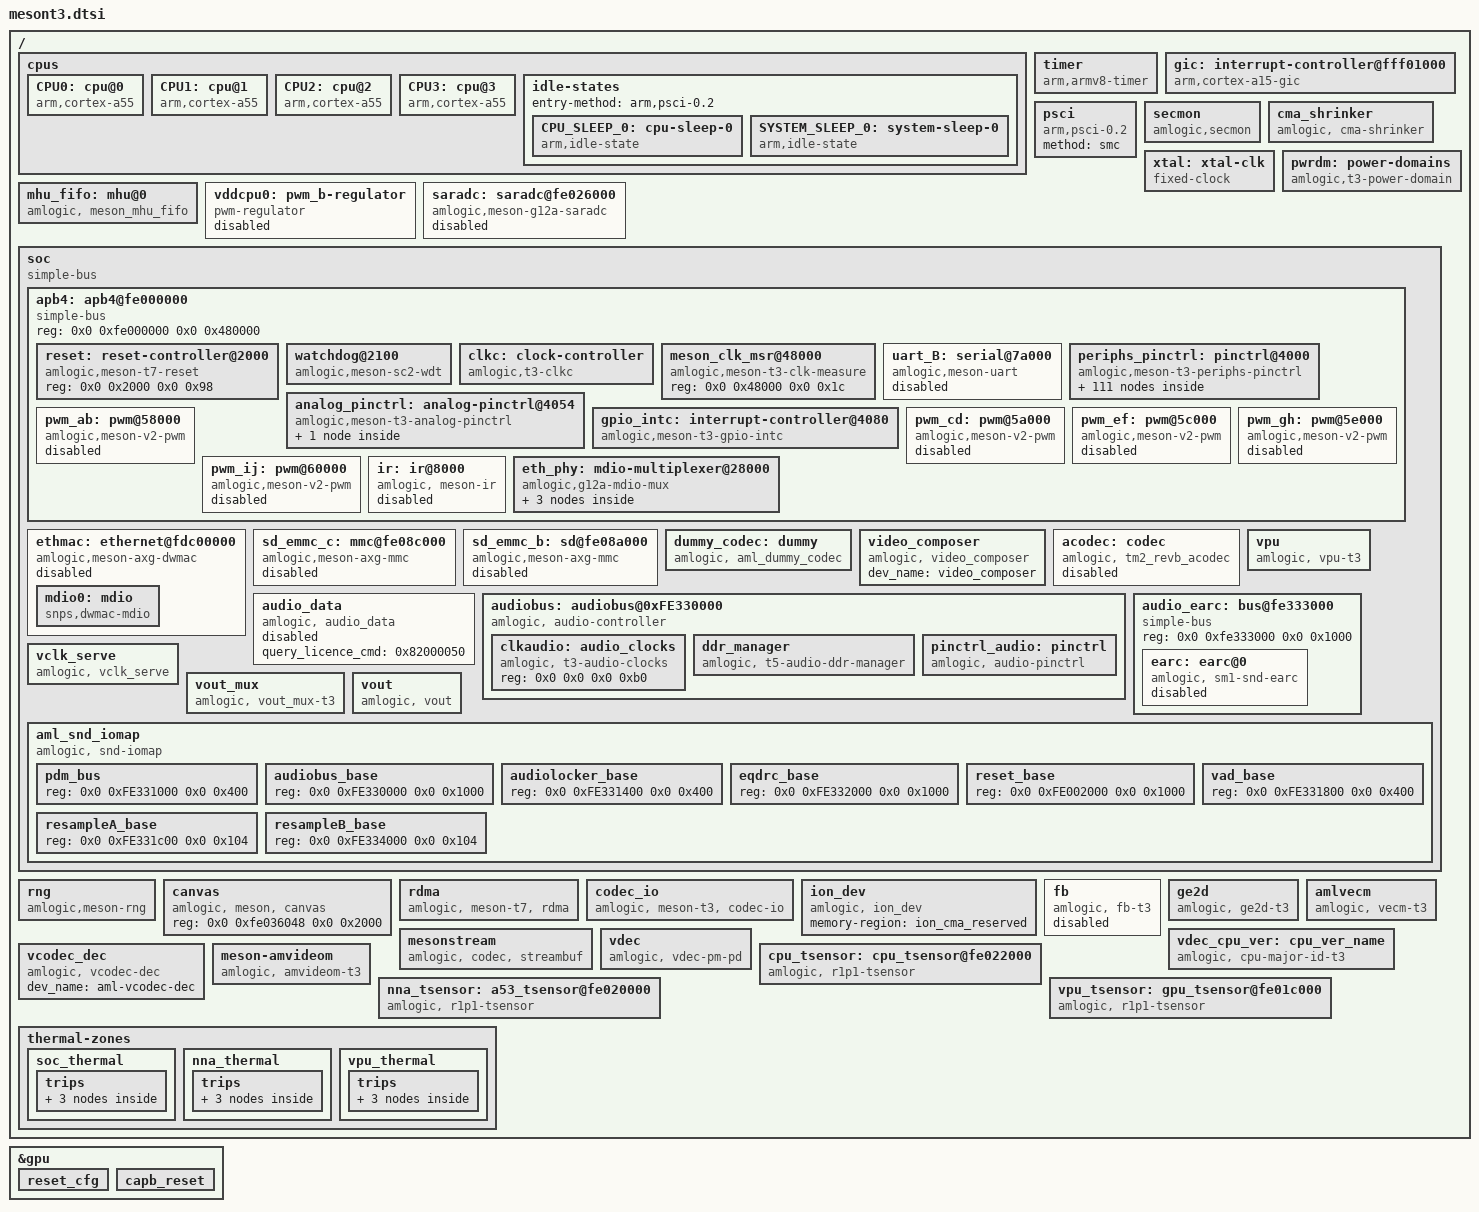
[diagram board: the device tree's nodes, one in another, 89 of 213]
// SPDX-License-Identifier: (GPL-2.0+ OR MIT)
/*
 * Copyright (c) 2021 Amlogic, Inc. All rights reserved.
 */

#include <dt-bindings/interrupt-controller/irq.h>
#include <dt-bindings/interrupt-controller/arm-gic.h>
#include <dt-bindings/reset/amlogic,meson-t3-reset.h>
#include <dt-bindings/clock/t3-clkc.h>
#include <dt-bindings/clock/amlogic,t3-audio-clk.h>
#include <dt-bindings/gpio/gpio.h>
#include <dt-bindings/gpio/meson-t3-gpio.h>
#include <dt-bindings/power/t3-pd.h>
#include <dt-bindings/pwm/pwm.h>
#include <dt-bindings/pwm/meson.h>
#include <dt-bindings/input/input.h>
#include <dt-bindings/input/meson_ir.h>
#include "meson-ir-map.dtsi"
#include "mesong12a-bifrost.dtsi"
/ {
	cpus:cpus {
		#address-cells = <2>;
		#size-cells = <0>;

		CPU0:cpu@0 {
			device_type = "cpu";
			compatible = "arm,cortex-a55","arm,armv8";
			reg = <0x0 0x0>;
			enable-method = "psci";
			cpu-idle-states = <&CPU_SLEEP_0 &SYSTEM_SLEEP_0>;
//			#cooling-cells = <2>;
//			clocks = <&clkc CLKID_CPU_CLK>,
//				<&clkc CLKID_CPU_DYN_CLK>,
//				<&clkc CLKID_SYS1_PLL>;
//			clock-names = "core_clk",
//				"low_freq_clk_parent",
//				"high_freq_clk_parent";
//			operating-points-v2 = <&cpu_opp_table1>;
			voltage-tolerance = <0>;
			clock-latency = <50000>;
			dynamic-power-coefficient = <230>;
		};

		CPU1:cpu@1{
			device_type = "cpu";
			compatible = "arm,cortex-a55","arm,armv8";
			reg = <0x0 0x1>;
			enable-method = "psci";
			cpu-idle-states = <&CPU_SLEEP_0 &SYSTEM_SLEEP_0>;
//			#cooling-cells = <2>;
//			clocks = <&clkc CLKID_CPU_CLK>,
//				<&clkc CLKID_CPU_DYN_CLK>,
//				<&clkc CLKID_SYS1_PLL>;
//			clock-names = "core_clk",
//				"low_freq_clk_parent",
//				"high_freq_clk_parent";
//			operating-points-v2 = <&cpu_opp_table1>;
			voltage-tolerance = <0>;
			clock-latency = <50000>;
			dynamic-power-coefficient = <230>;
		};

		CPU2:cpu@2 {
			device_type = "cpu";
			compatible = "arm,cortex-a55","arm,armv8";
			reg = <0x0 0x2>;
			enable-method = "psci";
			cpu-idle-states = <&CPU_SLEEP_0 &SYSTEM_SLEEP_0>;
//			#cooling-cells = <2>;
//			clocks = <&clkc CLKID_CPU_CLK>,
//				<&clkc CLKID_CPU_DYN_CLK>,
//				<&clkc CLKID_SYS1_PLL>;
//			clock-names = "core_clk",
//				"low_freq_clk_parent",
//				"high_freq_clk_parent";
//			operating-points-v2 = <&cpu_opp_table1>;
			voltage-tolerance = <0>;
			clock-latency = <50000>;
			dynamic-power-coefficient = <230>;
		};

		CPU3:cpu@3 {
			device_type = "cpu";
			compatible = "arm,cortex-a55","arm,armv8";
			reg = <0x0 0x3>;
			enable-method = "psci";
			cpu-idle-states = <&CPU_SLEEP_0 &SYSTEM_SLEEP_0>;
//			#cooling-cells = <2>;
//			clocks = <&clkc CLKID_CPU_CLK>,
//				<&clkc CLKID_CPU_DYN_CLK>,
//				<&clkc CLKID_SYS1_PLL>;
//			clock-names = "core_clk",
//				"low_freq_clk_parent",
//				"high_freq_clk_parent";
//			operating-points-v2 = <&cpu_opp_table1>;
			voltage-tolerance = <0>;
			clock-latency = <50000>;
		};

		idle-states {
			entry-method = "arm,psci-0.2";
			CPU_SLEEP_0: cpu-sleep-0 {
					compatible = "arm,idle-state";
					arm,psci-suspend-param = <0x0010000>;
					local-timer-stop;
					entry-latency-us = <4000>;
					exit-latency-us = <5000>;
					min-residency-us = <10000>;
			};
			SYSTEM_SLEEP_0: system-sleep-0 {
					compatible = "arm,idle-state";
					arm,psci-suspend-param = <0x0000000>;
					entry-latency-us = <0x3fffffff>;
					exit-latency-us = <0x40000000>;
					min-residency-us = <0xffffffff>;
			};
		};
	};

	timer {
		compatible = "arm,armv8-timer";
		interrupts = <GIC_PPI 13 0xff08>,
				<GIC_PPI 14 0xff08>,
				<GIC_PPI 11 0xff08>,
				<GIC_PPI 10 0xff08>;
	};

	gic: interrupt-controller@fff01000 {
		compatible = "arm,cortex-a15-gic", "arm,cortex-a9-gic";
		#interrupt-cells = <3>;
		#address-cells = <0>;
		interrupt-controller;
		reg = <0x0 0xfff01000 0 0x1000>,
		      <0x0 0xfff02000 0 0x0100>;
		interrupts = <GIC_PPI 9 0xf04>;
	};

	psci {
		compatible = "arm,psci-0.2";
		method = "smc";
	};

	secmon {
	    compatible = "amlogic,secmon";
		memory-region = <&secmon_reserved>;
		reserve_mem_size = <0x00300000>;
		in_base_func = <0x82000020>;
		out_base_func = <0x82000021>;
		clear_range = <0x05100000 0x200000>;
	};

	cma_shrinker: cma_shrinker {
		compatible = "amlogic, cma-shrinker";
		status = "okay";
		adj  = <0 100 200 250 900 950>;
		free = <8192 12288 16384 24576 28672 32768>;
	};

	xtal: xtal-clk {
		compatible = "fixed-clock";
		clock-frequency = <24000000>;
		clock-output-names = "xtal";
		#clock-cells = <0>;
	};

	pwrdm: power-domains {
		compatible = "amlogic,t3-power-domain";
		#power-domain-cells = <1>;
		status = "okay";
	};

	mhu_fifo: mhu@0 {
		status = "okay";
		compatible = "amlogic, meson_mhu_fifo";
		reg = <0x0 0xfe006000 0x0 0x1000>,  /* mhu wr fifo */
		      <0x0 0xfe007180 0x0 0x80>,   /* mhu set reg */
		      <0x0 0xfe007200 0x0 0x80>,   /* mhu clr reg */
		      <0x0 0xfe007280 0x0 0x80>,   /* mhu sts reg */
		      <0x0 0xfe007040 0x0 0xc0>;   /* mhu irqctrl reg */
		interrupts = <0 248 1>;   /* irq top */
		mbox-irqmax = <64>;
		mbox-irqctlr = <0>;
		mbox-nums = <4>;
		mbox-names = "dsp_dev",
			     "ap_to_dspa",
			     "ao_dev",
			     "ap_to_ao";
		mboxes = <&mhu_fifo 0>,
			 <&mhu_fifo 1>,
			 <&mhu_fifo 2>,
			 <&mhu_fifo 3>;
		mbox-id = <0x0 0x1 0x2 0x3>;
		mbox-wr-rd = <1>;
		#mbox-cells = <1>;
	};

	vddcpu0: pwm_b-regulator {
		compatible = "pwm-regulator";
		pwms = <&pwm_ab MESON_PWM_1 1500 0>;
		regulator-name = "vddcpu0";
		regulator-min-microvolt = <689000>;
		regulator-max-microvolt = <1049000>;
		regulator-always-on;
		max-duty-cycle = <1500>;
		/* Voltage Duty-Cycle */
		voltage-table = <1049000 0>,
				<1039000 3>,
				<1029000 6>,
				<1019000 9>,
				<1009000 12>,
				<999000 14>,
				<989000 17>,
				<979000 20>,
				<969000 23>,
				<959000 26>,
				<949000 29>,
				<939000 31>,
				<929000 34>,
				<919000 37>,
				<909000 40>,
				<899000 43>,
				<889000 45>,
				<879000 48>,
				<869000 51>,
				<859000 54>,
				<849000 56>,
				<839000 59>,
				<829000 62>,
				<819000 65>,
				<809000 68>,
				<799000 70>,
				<789000 73>,
				<779000 76>,
				<769000 79>,
				<759000 81>,
				<749000 84>,
				<739000 87>,
				<729000 89>,
				<719000 92>,
				<709000 95>,
				<699000 98>,
				<689000 100>;
		status = "disabled";
	};

	saradc: saradc@fe026000 {
		compatible = "amlogic,meson-g12a-saradc",
			   "amlogic,meson-saradc";
		status = "disabled";
		#io-channel-cells = <1>;
		clocks = <&xtal>,
		    <&clkc CLKID_SYS_CLK_SAR_ADC>,
		    <&clkc CLKID_SARADC>,
		    <&clkc CLKID_SARADC_SEL>;
		clock-names = "clkin", "core",
		    "adc_clk", "adc_sel";
		interrupts = <GIC_SPI 181 IRQ_TYPE_EDGE_RISING>;
		reg = <0x00 0xfe026000 0x00 0x48>;
	};

	soc {
		compatible = "simple-bus";
		#address-cells = <2>;
		#size-cells = <2>;
		ranges;

		apb4: apb4@fe000000 {
			compatible = "simple-bus";
			reg = <0x0 0xfe000000 0x0 0x480000>;
			#address-cells = <2>;
			#size-cells = <2>;
			ranges = <0x0 0x0 0x0 0xfe000000 0x0 0x480000>;

			reset: reset-controller@2000 {
				compatible = "amlogic,meson-t7-reset";
				reg = <0x0 0x2000 0x0 0x98>;
				#reset-cells = <1>;
			};

			watchdog@2100 {
				compatible = "amlogic,meson-sc2-wdt";
				status = "okay";
				/* 0:userspace, 1:kernel */
				amlogic,feed_watchdog_mode = <1>;
				reg = <0x0 0x2100 0x0 0x10>;
				clocks = <&xtal>;
			};

			clkc: clock-controller {
				compatible = "amlogic,t3-clkc";
				#clock-cells = <1>;
				reg = <0x0 0x0 0x0 0x230>,
				      <0x0 0x8000 0x0 0x3e4>,
				      <0x0 0xe140 0x0 0x20>;
				reg-names = "basic", "pll",
					    "cpu_clk";
				clocks = <&xtal>;
				clock-names = "xtal";
				status = "okay";
			};

			meson_clk_msr@48000 {
				compatible = "amlogic,meson-t3-clk-measure";
				reg = <0x0 0x48000 0x0 0x1c>;
			};

			uart_B: serial@7a000 {
				compatible = "amlogic,meson-uart";
				reg = <0x0 0x7a000 0x0 0x18>;
				interrupts = <0 169 1>;
				status = "disabled";
				clocks = <&xtal>;
				clock-names = "clk_uart";
				xtal_tick_en = <2>;
				fifosize = < 64 >;
				pinctrl-names = "default";
				//pinctrl-0 = <&a_uart_pins1>;
			};

			periphs_pinctrl: pinctrl@4000 {
				compatible = "amlogic,meson-t3-periphs-pinctrl";
				#address-cells = <2>;
				#size-cells = <2>;
				ranges;

				gpio: bank@4000 {
					reg = <0x0 0x4000 0x0 0x0054>,
					      <0x0 0x40c0 0x0 0x030c>;
					reg-names = "mux", "gpio";
					gpio-controller;
					#gpio-cells = <2>;
					gpio-ranges = <&periphs_pinctrl 0 0 136>;
				};
			};

			analog_pinctrl: analog-pinctrl@4054 {
				compatible = "amlogic,meson-t3-analog-pinctrl";
				#address-cells = <2>;
				#size-cells = <2>;
				ranges;

				analog_gpio: analog-bank@4054 {
					reg = <0x0 0x4054 0x0 0x0008>,
					      <0x0 0x43cc 0x0 0x0008>;
					reg-names = "mux", "gpio";
					gpio-controller;
					#gpio-cells = <2>;
					gpio-ranges = <&analog_pinctrl 0 0 3>;
				};
			};

			gpio_intc: interrupt-controller@4080 {
				compatible = "amlogic,meson-t3-gpio-intc",
					     "amlogic,meson-gpio-intc";
				reg = <0x0 0x4080 0x0 0x20>;
				interrupt-controller;
				#interrupt-cells = <2>;
				amlogic,channel-interrupts =
					<10 11 12 13 14 15 16 17 18 19 20 21>;
			};

			pwm_ab: pwm@58000 {
				compatible = "amlogic,meson-v2-pwm";
				reg = <0x0 0x58000 0x0 0x24>;
				#pwm-cells = <3>;
				clocks = <&clkc CLKID_PWM_A>,
						<&clkc CLKID_PWM_B>;
				clock-names = "clkin0", "clkin1";
				status = "disabled";
			};

			pwm_cd: pwm@5a000 {
				compatible = "amlogic,meson-v2-pwm";
				reg = <0x0 0x5a000 0x0 0x24>;
				#pwm-cells = <3>;
				clocks = <&clkc CLKID_PWM_C>,
						<&clkc CLKID_PWM_D>;
				clock-names = "clkin0", "clkin1";
				status = "disabled";
			};

			pwm_ef: pwm@5c000 {
				compatible = "amlogic,meson-v2-pwm";
				reg = <0x0 0x5c000 0x0 0x24>;
				#pwm-cells = <3>;
				clocks = <&clkc CLKID_PWM_E>,
						<&clkc CLKID_PWM_F>;
				clock-names = "clkin0", "clkin1";
				status = "disabled";
			};

			pwm_gh: pwm@5e000 {
				compatible = "amlogic,meson-v2-pwm";
				reg = <0x0 0x5e000 0x0 0x24>;
				#pwm-cells = <3>;
				clocks = <&clkc CLKID_PWM_G>,
						<&clkc CLKID_PWM_H>;
				clock-names = "clkin0", "clkin1";
				status = "disabled";
			};

			pwm_ij: pwm@60000 {
				compatible = "amlogic,meson-v2-pwm";
				reg = <0x0 0x60000 0x0 0x24>;
				#pwm-cells = <3>;
				clocks = <&clkc CLKID_PWM_I>,
						<&clkc CLKID_PWM_J>;
				clock-names = "clkin0", "clkin1";
				status = "disabled";
			};

			ir: ir@8000 {
				compatible = "amlogic, meson-ir";
				reg = <0x0 0x84040 0x0 0x44>,
					<0x0 0x84000 0x0 0x20>;
				status = "disabled";
				protocol = <REMOTE_TYPE_NEC>;
				interrupts = <GIC_SPI 22 IRQ_TYPE_EDGE_RISING>;
				map = <&custom_maps>;
				max_frame_time = <200>;
			};

			eth_phy: mdio-multiplexer@28000 {
				compatible = "amlogic,g12a-mdio-mux";
				reg = <0x0 0x28000 0x0 0xa4>;

				clocks = <&clkc CLKID_SYS_CLK_ETHPHY>,
					 <&xtal>,
					 <&clkc CLKID_MPLL_50M>;
				clock-names = "pclk", "clkin0", "clkin1";
				mdio-parent-bus = <&mdio0>;
				#address-cells = <1>;
				#size-cells = <0>;
				enet_type = <5>;
				tx_amp_src = <0xFE010330>;

				ext_mdio: mdio@0 {
					reg = <0>;
					#address-cells = <1>;
					#size-cells = <0>;
				};

				int_mdio: mdio@1 {
					reg = <1>;
					#address-cells = <1>;
					#size-cells = <0>;

					internal_ephy: ethernet_phy@8 {
						compatible = "ethernet-phy-id0180.3301",
							     "ethernet-phy-ieee802.3-c22";
						interrupts = <GIC_SPI 340 IRQ_TYPE_LEVEL_HIGH>;
						reg = <8>;
						max-speed = <100>;
					};
				};
			};
		};

		ethmac: ethernet@fdc00000 {
			compatible = "amlogic,meson-axg-dwmac",
				     "snps,dwmac-3.70a",
				     "snps,dwmac";
			reg = <0x0 0xfdc00000 0x0 0x10000>,
			      <0x0 0xfe024000 0x0 0x8>;
			interrupts = <GIC_SPI 74 IRQ_TYPE_LEVEL_HIGH>;
			interrupt-names = "macirq";
			power-domains = <&pwrdm PDID_T3_ETH>;
			clocks = <&clkc CLKID_SYS_CLK_ETH>,
				 <&clkc CLKID_FCLK_DIV2>,
				 <&clkc CLKID_MPLL2>;
			clock-names = "stmmaceth", "clkin0", "clkin1";
			rx-fifo-depth = <4096>;
			tx-fifo-depth = <2048>;
			/*1:inphy; 2:exphy;*/
			internal_phy = <1>;
			status = "disabled";

			mdio0: mdio {
				#address-cells = <1>;
				#size-cells = <0>;
				compatible = "snps,dwmac-mdio";
			};
		};

		sd_emmc_c: mmc@fe08c000 {
			compatible = "amlogic,meson-axg-mmc";
			reg = <0x0 0xfe08c000 0x0 0x800>,
				<0x0 0xfe000168 0x0 0x4>,
				<0x0 0xfe004000 0x0 0x4>;
			interrupts = <GIC_SPI 178 IRQ_TYPE_EDGE_RISING>;
			status = "disabled";
			clocks = <&clkc CLKID_SYS_CLK_SD_EMMC_C>,
				<&clkc CLKID_SD_EMMC_C_CLK_SEL>,
				 <&clkc CLKID_SD_EMMC_C_CLK>,
				 <&xtal>,
				 <&clkc CLKID_FCLK_DIV2>,
				 <&clkc CLKID_GP0_PLL>;
			clock-names = "core", "mux0", "mux1",
					"clkin0", "clkin1", "clkin2";
			card_type = <1>;
			src_clk_rate = <1152000000>;
			mmc_debug_flag;
			ignore_desc_busy;
			tx_delay = <16>;
		//	resets = <&reset RESET_SD_EMMC_C>;
		};

		sd_emmc_b: sd@fe08a000 {
			compatible = "amlogic,meson-axg-mmc";
			reg = <0x0 0xfe08a000 0x0 0x800>,
				<0x0 0xfe00016c 0x0 0x4>,
				<0x0 0xfe00401c 0x0 0x4>;
			interrupts = <GIC_SPI 177 IRQ_TYPE_EDGE_RISING>;
			status = "disabled";
			clocks = <&clkc CLKID_SYS_CLK_SD_EMMC_B>,
				<&clkc CLKID_SD_EMMC_B_CLK_SEL>,
				 <&clkc CLKID_SD_EMMC_B_CLK>,
				 <&xtal>,
				 <&clkc CLKID_FCLK_DIV2>;
			clock-names = "core", "mux0", "mux1",
					"clkin0", "clkin1";
			card_type = <5>;
			mmc_debug_flag;
			//resets = <&reset RESET_SD_EMMC_B>;
		};

//		sd_emmc_a: sdio@fe088000 {
//			compatible = "amlogic,meson-axg-mmc";
//			reg = <0x0 0xfe088000 0x0 0x800>,
//				<0x0 0xfe00016c 0x0 0x4>,
//				<0x0 0xfe004008 0x0 0x4>;
//			interrupts = <GIC_SPI 176 IRQ_TYPE_LEVEL_HIGH>;
//			status = "disabled";
//			clocks = <&clkc CLKID_SD_EMMC_A>,
//				<&clkc CLKID_SD_EMMC_A_CLK_MUX>,
//				 <&clkc CLKID_SD_EMMC_A_CLK>,
//				 <&xtal>,
//				 <&clkc CLKID_GP0_PLL>;
//			clock-names = "core", "mux0", "mux1",
//					"clkin0", "clkin1";
//			card_type = <3>;
//			cap-sdio-irq;
//			keep-power-in-suspend;
//			src_clk_rate = <1152000000>;
//			use_intf3_tuning;
//			mmc_debug_flag;
//			//resets = <&reset RESET_SD_EMMC_A>;
//		};

		dummy_codec:dummy{
			#sound-dai-cells = <0>;
			compatible = "amlogic, aml_dummy_codec";
			status = "okay";
		};
		video_composer {
			compatible = "amlogic, video_composer";
			dev_name = "video_composer";
			status = "okay";
		};
		acodec:codec {
			#sound-dai-cells = <0>;
			compatible = "amlogic, tm2_revb_acodec";
			reg = <0x0 0xff632000 0x0 0x1c>;
			tdmout_index = <0>;
			tdmin_index = <0>;
			dat0_ch_sel = <1>;

			status = "disabled";
		};

		audio_data: audio_data {
			compatible = "amlogic, audio_data";
			query_licence_cmd = <0x82000050>;
			status = "disabled";
		};

		audiobus: audiobus@0xFE330000 {
			compatible = "amlogic, audio-controller", "simple-bus";
			reg = <0x0 0xFE330000 0x0 0x3000>;
			#address-cells = <2>;
			#size-cells = <2>;
			ranges = <0x0 0x0 0x0 0xFE330000 0x0 0x3000>;

			power-domains = <&pwrdm PDID_T3_AUDIO>;
			status = "okay";

			clkaudio: audio_clocks {
				compatible = "amlogic, t3-audio-clocks";
				#clock-cells = <1>;
				reg = <0x0 0x0 0x0 0xb0>;
				status = "okay";
			};
			ddr_manager {
				compatible =
					"amlogic, t5-audio-ddr-manager";
				interrupts = <
					GIC_SPI 32 IRQ_TYPE_EDGE_RISING
					GIC_SPI 33 IRQ_TYPE_EDGE_RISING
					GIC_SPI 34 IRQ_TYPE_EDGE_RISING
					GIC_SPI 45 IRQ_TYPE_EDGE_RISING
					GIC_SPI 36 IRQ_TYPE_EDGE_RISING
					GIC_SPI 37 IRQ_TYPE_EDGE_RISING
					GIC_SPI 38 IRQ_TYPE_EDGE_RISING
					GIC_SPI 46 IRQ_TYPE_EDGE_RISING
				>;
				interrupt-names =
					"toddr_a", "toddr_b", "toddr_c",
					"toddr_d",
					"frddr_a", "frddr_b", "frddr_c",
					"frddr_d";
				status = "okay";
			};

		pinctrl_audio: pinctrl {
				compatible = "amlogic, audio-pinctrl";
				status = "okay";
			};
		};/* end of audiobus*/

		vpu: vpu {
			compatible = "amlogic, vpu-t3";
			status = "okay";
			reg =   <0x0 0xfe000000 0x0 0x100    /* clk */
				0x0 0xfe00c000 0x0 0x70     /* pwrctrl */
				0x0 0xff000000 0x0 0xa000>; /* vcbus */
			clocks = <&clkc CLKID_VAPB>,
				<&clkc CLKID_VPU_0>,
				<&clkc CLKID_VPU_1>,
				<&clkc CLKID_VPU>;
			clock-names =   "vapb_clk",
					"vpu_clk0",
					"vpu_clk1",
					"vpu_clk";
			clk_level = <7>;
			/* 0: 100.0M    1: 166.7M    2: 200.0M    3: 250.0M */
			/* 4: 333.3M    5: 400.0M    6: 500.0M    7: 666.7M */
		};

		/* eARC */
		audio_earc: bus@fe333000 {
			compatible = "simple-bus";
			reg = <0x0 0xfe333000 0x0 0x1000>;
			#address-cells = <2>;
			#size-cells = <2>;
			ranges = <0x0 0x0 0x0 0xfe333000 0x0 0x1000>;

			earc: earc@0 {
				compatible = "amlogic, sm1-snd-earc";
				#sound-dai-cells = <0>;

				status = "disabled";

				reg =	<0x0 0x0 0x0 0x400>,
					<0x0 0x400 0x0 0x200>,
					<0x0 0x600 0x0 0x200>;
				reg-names = "tx_cmdc",
					"tx_dmac",
					"tx_top";

				clocks = < &clkaudio CLKID_EARCTX_CMDC
					&clkaudio CLKID_EARCTX_DMAC
					&clkc CLKID_FCLK_DIV4
					&clkc CLKID_MPLL1
					>;
				clock-names =
					"tx_cmdc",
					"tx_dmac",
					"tx_cmdc_srcpll",
					"tx_dmac_srcpll";

				interrupts = <
					GIC_SPI 49 IRQ_TYPE_LEVEL_HIGH>;
				interrupt-names ="earc_tx";
			};
		};

		vclk_serve: vclk_serve {
			compatible = "amlogic, vclk_serve";
			status = "okay";
			reg = <0x0 0xfe008000 0x0 0x400    /* ana reg */
				0x0 0xfe000000 0x0 0x4a0>; /* clk reg */
		};

		vout_mux: vout_mux {
			compatible = "amlogic, vout_mux-t3";
			status = "okay";
		};

		vout: vout {
			compatible = "amlogic, vout";
			status = "okay";
		};

		/* Sound iomap */
		aml_snd_iomap {
			compatible = "amlogic, snd-iomap";
			status = "okay";
			#address-cells=<2>;
			#size-cells=<2>;
			ranges;
			pdm_bus {
				reg = <0x0 0xFE331000 0x0 0x400>;
			};
			audiobus_base {
				reg = <0x0 0xFE330000 0x0 0x1000>;
			};
			audiolocker_base {
				reg = <0x0 0xFE331400 0x0 0x400>;
			};
			eqdrc_base {
				reg = <0x0 0xFE332000 0x0 0x1000>;
			};
			reset_base {
				reg = <0x0 0xFE002000 0x0 0x1000>;
			};
			vad_base {
				reg = <0x0 0xFE331800 0x0 0x400>;
			};
			resampleA_base {
				reg = <0x0 0xFE331c00 0x0 0x104>;
			};
			resampleB_base {
				reg = <0x0 0xFE334000 0x0 0x104>;
			};
		};
	};

	rng {
		compatible = "amlogic,meson-rng";
		status = "okay";
		#address-cells = <2>;
		#size-cells = <2>;
		reg = <0x0 0xfe440788 0x0 0x0c>;
		quality = /bits/ 16 <1000>;
		version = <2>;
	};

	canvas: canvas {
		compatible = "amlogic, meson, canvas";
		status = "okay";
		reg = <0x0 0xfe036048 0x0 0x2000>;
	};

	rdma {
		compatible = "amlogic, meson-t7, rdma";
		status = "okay";
		interrupts = <GIC_SPI 215 IRQ_TYPE_EDGE_RISING>;
		interrupt-names = "rdma";
		/* after sc2 */
		reset-names = "rdma";
		resets = <&reset RESET_RDMA>;
		rdma_table_page_count = <16>;
	};

	codec_io: codec_io {
		compatible = "amlogic, meson-t3, codec-io";
		status = "okay";
		#address-cells=<2>;
		#size-cells=<2>;
		ranges;
		reg =	<0x0 0xfe002000 0x0 0x2000>,
			<0x0 0xfe320000 0x0 0x10000>,
			<0x0 0x0 0x0 0x0>,
			<0x0 0x0 0x0 0x00>,
			<0x0 0xff000000 0x0 0x40000>,
			<0x0 0xfe036000 0x0 0x2000>,
			<0x0 0x0 0x0 0x0>;
		reg-names = "cbus",
			    "dosbus",
			    "hiubus",
			    "aobus",
			    "vcbus",
			    "dmcbus",
			    "efusebus";
	};

	ion_dev {
		compatible = "amlogic, ion_dev";
		memory-region = <&ion_cma_reserved>;
	};

	fb: fb {
		compatible = "amlogic, fb-t3";
		memory-region = <&logo_reserved>;
		status = "disabled";
		interrupts = <GIC_SPI 197 IRQ_TYPE_EDGE_RISING
			GIC_SPI 215 IRQ_TYPE_EDGE_RISING>;
		interrupt-names = "viu-vsync", "rdma";
		/* uboot logo,fb0/fb1 memory size,if afbcd fb0=0x01851000*/
		display_mode_default = "1080p60hz";
		scale_mode = <1>;
		/** 0:VPU free scale 1:OSD free scale 2:OSD super scale */
		display_size_default = <1920 1080 1920 2160 32>;
		/*1920*1080*4*3 = 0x17BB000*/
	};

	ge2d {
		compatible = "amlogic, ge2d-t3";
		status = "okay";
		interrupts = <GIC_SPI 217 IRQ_TYPE_EDGE_RISING>;
		interrupt-names = "ge2d";
		clocks = <&clkc CLKID_VAPB>,
			<&clkc CLKID_SYS_CLK_G2D>,
			<&clkc CLKID_GE2D_GATE>;
		clock-names = "clk_vapb_0",
			"clk_ge2d",
			"clk_ge2d_gate";
		reg = <0x0 0xff040000 0x0 0x100>;
		power-domains = <&pwrdm PDID_T3_GE2D>;
	};

	amlvecm: amlvecm {
		compatible = "amlogic, vecm-t3";
		dev_name = "aml_vecm";
		clocks = <&clkc CLKID_VID_LOCK>;
		clock-names = "cts_vid_lock_clk";
	};

	mesonstream {
		compatible = "amlogic, codec, streambuf";
		dev_name = "mesonstream";
		status = "okay";
		clocks = <&clkc CLKID_SYS_CLK_DOS
			&clkc CLKID_VDEC
			&clkc CLKID_HCODEC
			&clkc CLKID_HEVCF
			&clkc CLKID_HEVCB>;
		clock-names = "vdec",
			"clk_vdec_mux",
			"clk_hcodec_mux",
			"clk_hevcf_mux",
			"clk_hevcb_mux";
		assigned-clock-parents = <&clkc CLKID_VDEC_0>,
			<&clkc CLKID_HEVCF_0>,
			<&clkc CLKID_HEVCB_0>;
		assigned-clocks = <&clkc CLKID_VDEC>,
			<&clkc CLKID_HEVCF>,
			<&clkc CLKID_HEVCB>;
	};

	vdec {
		compatible = "amlogic, vdec-pm-pd";
		dev_name = "vdec.0";
		status = "okay";
		interrupts = <0 3 1
			0 23 1
			0 32 1
			0 91 1
			0 92 1
			0 93 1
			0 72 1>;
		interrupt-names = "vsync",
			"demux",
			"parser",
			"mailbox_0",
			"mailbox_1",
			"mailbox_2",
			"parser_b";
		power-domains = <&pwrdm PDID_T3_DOS_VDEC>,
			<&pwrdm PDID_T3_DOS_HEVC>;
		power-domain-names = "pwrc-vdec",
			"pwrc-hevc";
	};
	vdec_cpu_ver: cpu_ver_name {
		compatible = "amlogic, cpu-major-id-t3";
	};
	vcodec_dec {
		compatible = "amlogic, vcodec-dec";
		dev_name = "aml-vcodec-dec";
		status = "okay";
	};

	meson-amvideom {
		compatible = "amlogic, amvideom-t3";
		dev_name = "amvideom";
		status = "okay";
		interrupts = <GIC_SPI 197 IRQ_TYPE_EDGE_RISING
			GIC_SPI 194 IRQ_TYPE_EDGE_RISING>;
		interrupt-names = "vsync", "vsync_viu2";
	};

	cpu_tsensor: cpu_tsensor@fe022000 {
		compatible = "amlogic, r1p1-tsensor";
		status = "okay";
		reg = <0x0 0xfe022000 0x0 0x50>;
		tsensor_id = <1>;
		cal_type = <0x11>;
		cal_coeff = <324 424 3159 9411>;
		rtemp = <115000>;
		interrupts = <GIC_SPI 83 IRQ_TYPE_LEVEL_HIGH>;
		clocks = <&clkc CLKID_TS_CLK>;
		clock-names = "ts_comp";
		#thermal-sensor-cells = <1>;
	};

	nna_tsensor: a53_tsensor@fe020000 {
		compatible = "amlogic, r1p1-tsensor";
		status = "okay";
		reg = <0x0 0xfe020000 0x0 0x50>;
		tsensor_id = <2>;
		cal_type = <0x11>;
		cal_coeff = <324 424 3159 9411>;
		rtemp = <115000>;
		interrupts = <GIC_SPI 84 IRQ_TYPE_LEVEL_HIGH>;
		clocks = <&clkc CLKID_TS_CLK>;
		clock-names = "ts_comp";
		#thermal-sensor-cells = <1>;
	};

	vpu_tsensor: gpu_tsensor@fe01c000 {
		compatible = "amlogic, r1p1-tsensor";
		status = "okay";
		reg = <0x0 0xfe01c000 0x0 0x50>;
		tsensor_id = <3>;
		cal_type = <0x11>;
		cal_coeff = <324 424 3159 9411>;
		rtemp = <115000>;
		interrupts = <GIC_SPI 85 IRQ_TYPE_LEVEL_HIGH>;
		clocks = <&clkc CLKID_TS_CLK>;
		clock-names = "ts_comp";
		#thermal-sensor-cells = <1>;
	};

//	meson_cooldev: meson-cooldev@0 {
//		status = "okay";
//		compatible = "amlogic, meson-cooldev";
//		cooling_devices {
//			cpucore_cool_cluster0 {
//				cluster_id = <0>;
//				node_name = "cpucore_cool0";
//				device_type = "cpucore";
//			};
//			cpucore_cool_cluster1 {
//				cluster_id = <1>;
//				node_name = "cpucore_cool1";
//				device_type = "cpucore";
//			};
//			gpufreq_cool {
//				dyn_coeff = <358>;
//				node_name = "bifrost";
//				device_type = "gpufreq";
//			};
//		};
//		cpucore_cool0:cpucore_cool0 {
//			#cooling-cells = <2>;
//		};
//		cpucore_cool1:cpucore_cool1 {
//			#cooling-cells = <2>;
//		};
//	};/*meson cooling devices end*/

	thermal-zones {
		soc_thermal: soc_thermal {
			polling-delay = <1000>;
			polling-delay-passive = <100>;
			sustainable-power = <5160>;
			thermal-sensors = <&cpu_tsensor 0>;
			trips {
				cpuswitch_on: trip-point@0 {
					temperature = <80000>;
					hysteresis = <5000>;
					type = "passive";
				};
				cpucontrol: trip-point@1 {
					temperature = <90000>;
					hysteresis = <5000>;
					type = "passive";
				};
				cpucritical: trip-point@2 {
					temperature = <110000>;
					hysteresis = <1000>;
					type = "critical";
				};
			};
		};
		nna_thermal: nna_thermal {
			polling-delay = <2000>;
			polling-delay-passive = <1000>;
			sustainable-power = <960>;
			thermal-sensors = <&nna_tsensor 1>;
			trips {
				nnaswitch_on: trip-point@0 {
					temperature = <90000>;
					hysteresis = <5000>;
					type = "passive";
				};
				nnacontrol: trip-point@1 {
					temperature = <100000>;
					hysteresis = <5000>;
					type = "passive";
				};
				nnacritical: trip-point@2 {
					temperature = <110000>;
					hysteresis = <1000>;
					type = "critical";
				};
			};
		};
		vpu_thermal: vpu_thermal {
			polling-delay = <2000>;
			polling-delay-passive = <1000>;
			sustainable-power = <400>;
			thermal-sensors = <&vpu_tsensor 2>;
			trips {
				vpuswitch_on: trip-point@0 {
					temperature = <85000>;
					hysteresis = <5000>;
					type = "passive";
				};
				vpucontrol: trip-point@1 {
					temperature = <95000>;
					hysteresis = <5000>;
					type = "passive";
				};
				vpucritical: trip-point@2 {
					temperature = <110000>;
					hysteresis = <1000>;
					type = "critical";
				};
			};
		};
	};/*thermal zone end*/
};

&periphs_pinctrl {
	emmc_pins: emmc {
		mux-0 {
			groups = "emmc_nand_d0",
				 "emmc_nand_d1",
				 "emmc_nand_d2",
				 "emmc_nand_d3",
				 "emmc_nand_d4",
				 "emmc_nand_d5",
				 "emmc_nand_d6",
				 "emmc_nand_d7",
				 "emmc_cmd";
			function = "emmc";
			bias-pull-up;
			drive-strength-microamp = <4000>;
		};

		mux-1 {
			groups = "emmc_clk";
			function = "emmc";
			bias-disable;
			drive-strength-microamp = <4000>;
		};
	};

	emmc_ds_pins: emmc-ds {
		mux {
			groups = "emmc_nand_ds";
			function = "emmc";
			bias-pull-down;
			drive-strength-microamp = <4000>;
		};
	};

	emmc_clk_gate_pins: emmc_clk_gate {
		mux {
			groups = "GPIOB_8";
			function = "gpio_periphs";
			bias-pull-down;
			drive-strength-microamp = <4000>;
		};
	};

	/* sdemmc portB */
	sd_clk_cmd_pins:sd_clk_cmd_pins {
		mux {
			groups = "sdcard_cmd";
			function = "sdcard";
			bias-pull-up;
			drive-strength-microamp = <4000>;
		};
		mux1 {
			groups = "sdcard_clk";
			function = "sdcard";
			bias-pull-up;
			drive-strength-microamp = <4000>;
		};
	};

	sd_all_pins:sd_all_pins {
		mux {
			groups = "sdcard_d0",
				   "sdcard_d1",
				   "sdcard_d2",
				   "sdcard_d3",
				   "sdcard_cmd";
			function = "sdcard";
			bias-pull-up;
			drive-strength-microamp = <4000>;
		};
		mux1 {
			groups = "sdcard_clk";
			function = "sdcard";
			bias-pull-up;
			drive-strength-microamp = <4000>;
		};
	};

	sd_clk_gate_pins: sd_clk_gate {
		mux {
			groups = "GPIOC_4";
			function = "gpio_periphs";
			bias-pull-down;
			drive-strength-microamp = <4000>;
		};
	};

	sd_all_pd_pins:sd_all_pd_pins {
		mux {
			groups = "GPIOC_0",
				   "GPIOC_1",
				   "GPIOC_2",
				   "GPIOC_3",
				   "GPIOC_4",
				   "GPIOC_5";
			function = "gpio_periphs";
			bias-pull-down;
			output-low;
		};
	};

	sd_1bit_pins:sd_1bit_pins {
		mux {
			groups = "sdcard_d0",
					"sdcard_cmd";
			function = "sdcard";
			bias-pull-up;
			drive-strength-microamp = <4000>;
		};
		mux1 {
			groups = "sdcard_clk";
			function = "sdcard";
			bias-pull-up;
			drive-strength-microamp = <4000>;
		};
	};

	pwm_a_pins1: pwm_a_pins1 {
		mux {
			groups = "pwm_a_e";
			function = "pwm_a";
		};
	};

	hdmirx_a_mux:hdmirx_a_mux {
		mux {
			groups = "hdmirx_hpd_a",
				"hdmirx_5vdet_a",
				"hdmirx_sda_a",
				"hdmirx_scl_a";
			function = "hdmirx";
		};
	};

	hdmirx_b_mux:hdmirx_b_mux {
		mux {
			groups = "hdmirx_hpd_b",
				"hdmirx_5vdet_b",
				"hdmirx_sda_b",
				"hdmirx_scl_b";
			function = "hdmirx";
		};
	};

	hdmirx_c_mux:hdmirx_c_mux {
		mux {
			groups = "hdmirx_hpd_c",
				"hdmirx_5vdet_c",
				"hdmirx_sda_c",
				"hdmirx_scl_c";
			function = "hdmirx";
		};
	};

	pwm_a_pins2: pwm_a_pins2 {
		mux {
			groups = "pwm_a_c";
			function = "pwm_a";
		};
	};

	pwm_b_pins1: pwm_b_pins1 {
		mux {
			groups = "pwm_b_e";
			function = "pwm_b";
		};
	};

	pwm_b_pins2: pwm_b_pins2 {
		mux {
			groups = "pwm_b_c";
			function = "pwm_b";
		};
	};

	pwm_b_pins3: pwm_b_pins3 {
		mux {
			groups = "pwm_b_z";
			function = "pwm_b";
		};
	};

	pwm_b_pins4: pwm_b_pins4 {
		mux {
			groups = "pwm_b_h14";
			function = "pwm_b";
		};
	};

	pwm_c_pins1: pwm_c_pins1 {
		mux {
			groups = "pwm_c_d5";
			function = "pwm_c";
		};
	};

	pwm_c_pins2: pwm_c_pins2 {
		mux {
			groups = "pwm_c_d7";
			function = "pwm_c";
		};
	};

	pwm_d_pins1: pwm_d_pins1 {
		mux {
			groups = "pwm_d_d6";
			function = "pwm_d";
		};
	};

	pwm_d_pins2: pwm_d_pins2 {
		mux {
			groups = "pwm_d_d9";
			function = "pwm_d";
		};
	};

	pwm_d_pins3: pwm_d_pins3 {
		mux {
			groups = "pwm_d_c";
			function = "pwm_d";
		};
	};

	pwm_d_pins4: pwm_d_pins4 {
		mux {
			groups = "pwm_d_z";
			function = "pwm_d";
		};
	};

	pwm_d_pins5: pwm_d_pins5 {
		mux {
			groups = "pwm_d_h5";
			function = "pwm_d";
		};
	};

	pwm_d_pins6: pwm_d_pins6 {
		mux {
			groups = "pwm_d_h12";
			function = "pwm_d";
		};
	};

	pwm_d_pins7: pwm_d_pins7 {
		mux {
			groups = "pwm_d_m1";
			function = "pwm_d";
		};
	};

	pwm_d_pins8: pwm_d_pins8 {
		mux {
			groups = "pwm_d_m24";
			function = "pwm_d";
		};
	};

	pwm_e_pins1: pwm_e_pins1 {
		mux {
			groups = "pwm_e_d";
			function = "pwm_e";
		};
	};

	pwm_e_pins2: pwm_e_pins2 {
		mux {
			groups = "pwm_e_z";
			function = "pwm_e";
		};
	};

	pwm_f_pins1: pwm_f_pins1 {
		mux {
			groups = "pwm_f_c";
			function = "pwm_f";
		};
	};

	pwm_f_pins2: pwm_f_pins2 {
		mux {
			groups = "pwm_f_h13";
			function = "pwm_f";
		};
	};

	pwm_f_pins3: pwm_f_pins3 {
		mux {
			groups = "pwm_f_m23";
			function = "pwm_f";
		};
	};

	pwm_f_pins4: pwm_f_pins4 {
		mux {
			groups = "pwm_f_m26";
			function = "pwm_f";
		};
	};

	pwm_g_pins1: pwm_g_pins1 {
		mux {
			groups = "pwm_g_m8";
			function = "pwm_g";
		};
	};

	pwm_g_pins2: pwm_g_pins2 {
		mux {
			groups = "pwm_g_z";
			function = "pwm_g";
		};
	};

	pwm_h_pins1: pwm_h_pins1 {
		mux {
			groups = "pwm_h_z";
			function = "pwm_h";
		};
	};

	pwm_h_pins2: pwm_h_pins2 {
		mux {
			groups = "pwm_h_m9";
			function = "pwm_h";
		};
	};

	pwm_i_pins1: pwm_i_pins1 {
		mux {
			groups = "pwm_i_z";
			function = "pwm_i";
		};
	};

	pwm_i_pins2: pwm_i_pins2 {
		mux {
			groups = "pwm_i_m10";
			function = "pwm_i";
		};
	};

	pwm_j_pins1: pwm_j_pins1 {
		mux {
			groups = "pwm_j_z";
			function = "pwm_j";
		};
	};

	pwm_j_pins2: pwm_j_pins2 {
		mux {
			groups = "pwm_j_m11";
			function = "pwm_j";
		};
	};

	pwm_c_hiz_pins: pwm_c_hiz_pins {
		mux {
			groups = "pwm_c_hiz_d";
			function = "pwm_c_hiz";
		};
	};

	pwm_d_hiz_pins: pwm_d_hiz_pins {
		mux {
			groups = "pwm_d_hiz_d";
			function = "pwm_d_hiz";
		};
	};

	lcd_vbyone_a_pins: lcd_vbyone_a_pin {
		mux {
			groups = "vx1_lockn","vx1_htpdn";
			function = "vx1";
		};
	};

	lcd_vbyone_a_off_pins: lcd_vbyone_a_off_pin {
		mux {
			groups = "GPIOH_0","GPIOH_8";
			function = "gpio_periphs";
			input-enable;
		};
	};

	lcd_tcon_p2p_pins: lcd_tcon_p2p_pin {
		mux {
			groups = "tcon_1","tcon_2","tcon_3",
				"tcon_4","tcon_5","tcon_6",
				"tcon_lock";
			function = "tcon";
		};
	};

	lcd_tcon_p2p_usit_pins: lcd_tcon_p2p_usit_pin {
		mux {
			groups = "tcon_1","tcon_2","tcon_3",
				"tcon_4","tcon_5","tcon_6",
				"tcon_sfc_h0";
			function = "tcon";
		};
	};

	lcd_tcon_p2p_off_pins: lcd_tcon_p2p_off_pin {
		mux {
			groups = "GPIOH_1","GPIOH_2","GPIOH_3",
				"GPIOH_4","GPIOH_5","GPIOH_6",
				"GPIOH_0";
				function = "gpio_periphs";
			input-enable;
		};
	};

	lcd_tcon_mlvds_pins: lcd_tcon_mlvds_pin {
		mux {
			groups = "tcon_0","tcon_1","tcon_2","tcon_3",
				"tcon_4","tcon_5","tcon_6";
			function = "tcon";
		};
	};

	lcd_tcon_mlvds_off_pins: lcd_tcon_mlvds_off_pin {
		mux {
			groups = "GPIOH_0","GPIOH_1","GPIOH_2","GPIOH_3",
				"GPIOH_4","GPIOH_5","GPIOH_6";
			function = "gpio_periphs";
			input-enable;
		};
	};

	remote_pins: remote_pin {
		mux {
			groups = "remote_input";
			function = "remote_input";
			bias-disable;
		};
	};

	spdifout_z: spdifout_z {
		mux { /* GPIOZ_19 */
			groups = "spdif_out_z19";
			function = "spdif_out";
		};
	};

	spdifout_z_mute: spdifout_z_mute {
		 mux { /* GPIOZ_19 */
			groups = "GPIOZ_19";
			function = "gpio_periphs";
			output-low;
		};
	};
};

&gpu{
	reg =   <0 0xFE400000 0 0x04000>, /*mali APB bus base address*/
		<0 0xFE002000 0 0x01000>, /*reset register*/
		<0 0xFF800000 0 0x01000>, /*aobus TODO update*/
		<0 0xFE000000 0 0x01000>, /*hiubus for clk cntl*/
		<0 0xFE002000 0 0x01000>; /*reset register*/

	interrupts = <0 144 4>, <0 145 4>, <0 146 4>;
	interrupt-names = "GPU", "MMU", "JOB";
	num_of_pp = <2>;
	system-coherency = <31>;
	clocks = <&clkc CLKID_MALI>;
	clock-names = "gpu_mux";

	/*
	 * Mali clocking is provided by two identical clock paths
	 * MALI_0 and MALI_1 muxed to a single clock by a glitch
	 * free mux to safely change frequency while running.
	 */
	assigned-clocks = <&clkc CLKID_MALI_0_SEL>,
			  <&clkc CLKID_MALI_0>,
			  <&clkc CLKID_MALI>; /* Glitch free mux */
	assigned-clock-parents = <&clkc CLKID_FCLK_DIV2P5>,
				 <0>, /* Do Nothing */
				 <&clkc CLKID_MALI_0>;
	assigned-clock-rates = <0>, /* Do Nothing */
			       <800000000>,
			       <0>; /* Do Nothing */

	tbl =  <&dvfs500_cfg
		&dvfs500_cfg
		&dvfs500_cfg
		&dvfs500_cfg
		&dvfs500_cfg
		&dvfs500_cfg>;

	reset_cfg:reset_cfg {
		reg_level = <0x11>;
		reg_mask = <0x21>;
		reg_bit = <2>;
	};

	capb_reset:capb_reset {
		reg_level = <0x11>;
		reg_mask = <0x21>;
		reg_bit = <1>;
	};
};
